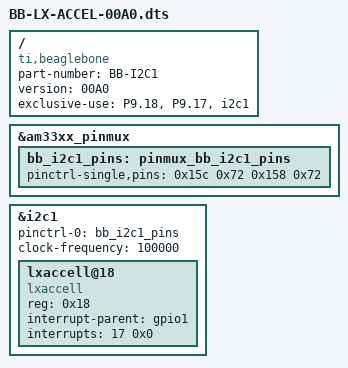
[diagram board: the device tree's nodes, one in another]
/dts-v1/;
/plugin/;

/ {
       compatible = "ti,beaglebone", "ti,beaglebone-black";

        /* identification */
        part-number = "BB-I2C1";
        version = "00A0";

        /* state the resources this cape uses */
        exclusive-use =
                /* the pin header uses */
                "P9.18",        /* i2c2_sda */
                "P9.17",        /* i2c2_scl */
                /* the hardware ip uses */
                "i2c1";

        fragment@0 {
                target = <&am33xx_pinmux>;
                __overlay__ {
                        bb_i2c1_pins: pinmux_bb_i2c1_pins {
                                pinctrl-single,pins = <
                                        0x15c 0x72    // spi0_d1.i2c1_sda,  SLEWCTRL_SLOW | IMPUT_PULLUP | MODE2
                                        0x158 0x72    // spi0_cs0.i2c1_scl, SLEWCTRL_SLOW | INPUT_PULLUP | MODE2
                                >;
                        };
                };
        };

        fragment@1 {
                target = <&i2c1>;    /* i2c1 is numbered correctly */
                __overlay__ {
                        status = "okay";
                        pinctrl-names = "default";
                        pinctrl-0 = <&bb_i2c1_pins>;

                        /* this is the configuration part */
                        clock-frequency = <100000>;

                        #address-cells = <1>;
                        #size-cells = <0>;

			 /* add any i2c devices on the bus here */

                        // Adding LIS3DH */
                           lxaccell@18{
                              compatible = "lxaccell";
                              reg = <0x18>;
                              interrupt-parent = <&gpio1>;
                              interrupts = <17 0x0>;
                        //      atmel,irq-gpio = <&gpio4 19 0>;
                        };

                };
        };

};
